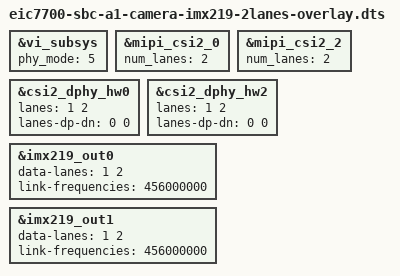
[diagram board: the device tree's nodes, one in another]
/dts-v1/;
/plugin/;

/ {
	fragment@0 {
		target =  <&vi_subsys>;
		__overlay__ {
			phy_mode = <5>;
		};
	};

	fragment@1 {
		target = <&mipi_csi2_0>;
		__overlay__ {
			num_lanes = <2>;
		};
	};

	fragment@2 {
		target = <&mipi_csi2_2>;
		__overlay__ {
			num_lanes = <2>;
		};
	};

	fragment@3 {
		target = <&csi2_dphy_hw0>;
		__overlay__ {
			lanes = <1 2>;
			lanes-dp-dn = <0 0>;
		};
	};

	fragment@4 {
		target = <&csi2_dphy_hw2>;
		__overlay__ {
			lanes = <1 2>;
			lanes-dp-dn = <0 0>;
		};
	};

	fragment@5 {
		target = <&imx219_out0>;
		__overlay__ {
			data-lanes = <1 2>;
			link-frequencies = /bits/ 64 <456000000>;
		};
	};

	fragment@6 {
		target = <&imx219_out1>;
		__overlay__ {
			data-lanes = <1 2>;
			link-frequencies = /bits/ 64 <456000000>;
		};
	};
};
